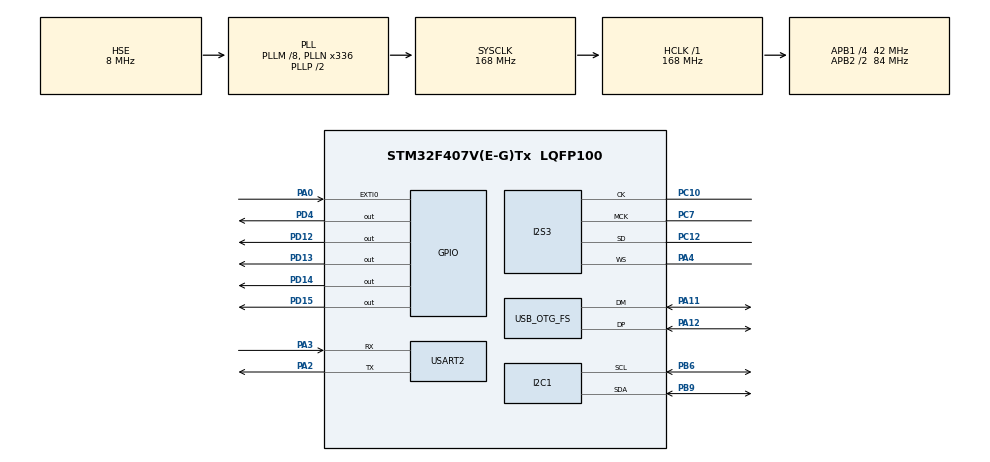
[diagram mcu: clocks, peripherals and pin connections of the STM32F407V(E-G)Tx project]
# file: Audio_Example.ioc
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Dma.Request0=SPI3_TX
Dma.Request1=USART2_RX
Dma.SPI3_TX.0.Direction=DMA_MEMORY_TO_PERIPH
Dma.SPI3_TX.0.FIFOMode=DMA_FIFOMODE_ENABLE
Dma.SPI3_TX.0.FIFOThreshold=DMA_FIFO_THRESHOLD_FULL
Dma.SPI3_TX.0.Instance=DMA1_Stream7
Dma.SPI3_TX.0.MemBurst=DMA_MBURST_SINGLE
Dma.SPI3_TX.0.MemDataAlignment=DMA_MDATAALIGN_HALFWORD
Dma.SPI3_TX.0.MemInc=DMA_MINC_ENABLE
Dma.SPI3_TX.0.Mode=DMA_CIRCULAR
Dma.SPI3_TX.0.PeriphBurst=DMA_PBURST_SINGLE
Dma.SPI3_TX.0.PeriphDataAlignment=DMA_PDATAALIGN_HALFWORD
Dma.SPI3_TX.0.PeriphInc=DMA_PINC_DISABLE
Dma.SPI3_TX.0.Priority=DMA_PRIORITY_LOW
Dma.USART2_RX.1.Direction=DMA_PERIPH_TO_MEMORY
Dma.USART2_RX.1.FIFOMode=DMA_FIFOMODE_DISABLE
Dma.USART2_RX.1.Instance=DMA1_Stream5
Dma.USART2_RX.1.MemDataAlignment=DMA_MDATAALIGN_BYTE
Dma.USART2_RX.1.MemInc=DMA_MINC_ENABLE
Dma.USART2_RX.1.Mode=DMA_NORMAL
Dma.USART2_RX.1.PeriphDataAlignment=DMA_PDATAALIGN_BYTE
Dma.USART2_RX.1.PeriphInc=DMA_PINC_DISABLE
Dma.USART2_RX.1.Priority=DMA_PRIORITY_LOW
I2S3.AudioFreq=I2S_AUDIOFREQ_48K
I2S3.ErrorAudioFreq=-2.34 %
I2S3.FullDuplexMode=I2S_FULLDUPLEXMODE_DISABLE
I2S3.Instance=SPI$Index
I2S3.RealAudioFreq=46.875 KHz
I2S3.VirtualMode=I2S_MODE_MASTER
Mcu.Family=STM32F4
Mcu.Name=STM32F407V(E-G)Tx
Mcu.Package=LQFP100
NVIC.DMA1_Stream5_IRQn=true\:0\:0\:false\:false\:true\:false\:true\:true
NVIC.DMA1_Stream7_IRQn=true\:0\:0\:false\:false\:true\:false\:true\:true
NVIC.EXTI0_IRQn=true\:0\:0\:false\:false\:true\:true\:true\:true
NVIC.OTG_FS_IRQn=true\:0\:0\:false\:false\:true\:false\:true\:true
NVIC.PriorityGroup=NVIC_PRIORITYGROUP_0
PA0-WKUP.Signal=GPXTI0
PA11.Mode=Device_Only
PA11.Signal=USB_OTG_FS_DM
PA12.Mode=Device_Only
PA12.Signal=USB_OTG_FS_DP
PA13.Mode=Serial_Wire
PA13.Signal=SYS_JTMS-SWDIO
PA14.Mode=Serial_Wire
PA14.Signal=SYS_JTCK-SWCLK
PA2.Mode=Asynchronous
PA2.Signal=USART2_TX
PA3.Mode=Asynchronous
PA3.Signal=USART2_RX
PA4.Mode=Half_Duplex_Master
PA4.Signal=I2S3_WS
PB6.Mode=I2C
PB6.Signal=I2C1_SCL
PB9.Mode=I2C
PB9.Signal=I2C1_SDA
PC10.Mode=Half_Duplex_Master
PC10.Signal=I2S3_CK
PC12.Mode=Half_Duplex_Master
PC12.Signal=I2S3_SD
PC7.Mode=Master_Clock_Activated
PC7.Signal=I2S3_MCK
PD12.Signal=GPIO_Output
PD13.Signal=GPIO_Output
PD14.Signal=GPIO_Output
PD15.Signal=GPIO_Output
PD4.Signal=GPIO_Output
PH0-OSC_IN.Mode=HSE-External-Oscillator
PH0-OSC_IN.Signal=RCC_OSC_IN
PH1-OSC_OUT.Mode=HSE-External-Oscillator
PH1-OSC_OUT.Signal=RCC_OSC_OUT
ProjectManager.HeapSize=0x200
ProjectManager.StackSize=0x400
ProjectManager.TargetToolchain=STM32CubeIDE
RCC.48MHZClocksFreq_Value=48000000
RCC.AHBFreq_Value=168000000
RCC.APB1CLKDivider=RCC_HCLK_DIV4
RCC.APB1Freq_Value=42000000
RCC.APB1TimFreq_Value=84000000
RCC.APB2CLKDivider=RCC_HCLK_DIV2
RCC.APB2Freq_Value=84000000
RCC.APB2TimFreq_Value=168000000
RCC.CortexFreq_Value=168000000
RCC.HCLKFreq_Value=168000000
RCC.HSE_VALUE=8000000
RCC.HSI_VALUE=16000000
RCC.LSE_VALUE=32768
RCC.PLLM=8
RCC.PLLN=336
RCC.PLLQ=7
RCC.SYSCLKFreq_VALUE=168000000
RCC.SYSCLKSource=RCC_SYSCLKSOURCE_PLLCLK
RCC.VCOOutputFreq_Value=336000000
USART2.VirtualMode=VM_ASYNC
USB_DEVICE.CLASS_NAME_FS=CDC
USB_DEVICE.VirtualMode-CDC_FS=Cdc
USB_DEVICE.VirtualModeFS=Cdc_FS
USB_OTG_FS.VirtualMode=Device_Only
VP_USB_DEVICE_VS_USB_DEVICE_CDC_FS.Mode=CDC_FS
board=STM32F407G-DISC1

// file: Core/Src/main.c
/* USER CODE BEGIN Header */
/**
  ******************************************************************************
  * @file           : main.c
  * @brief          : Main program body
  ******************************************************************************
  * @attention
  *
  * Copyright (c) 2024 STMicroelectronics.
  * All rights reserved.
  *
  * This software is licensed under terms that can be found in the LICENSE file
  * in the root directory of this software component.
  * If no LICENSE file comes with this software, it is provided AS-IS.
  *
  ******************************************************************************
  */
/* USER CODE END Header */
#include "main.h"
#include "usb_device.h"

/* USER CODE BEGIN Includes */
#include "interface.h"
/* USER CODE END Includes */

I2C_HandleTypeDef hi2c1;

I2S_HandleTypeDef hi2s3;
DMA_HandleTypeDef hdma_spi3_tx;

UART_HandleTypeDef huart2;
DMA_HandleTypeDef hdma_usart2_rx;

void SystemClock_Config(void);
static void MX_GPIO_Init(void);
static void MX_DMA_Init(void);
static void MX_I2C1_Init(void);
static void MX_I2S3_Init(void);
static void MX_USART2_UART_Init(void);

int main(void)
{

  /* MCU Configuration--------------------------------------------------------*/

  /* Reset of all peripherals, Initializes the Flash interface and the Systick. */
  HAL_Init();

  /* Configure the system clock */
  SystemClock_Config();

  /* Initialize all configured peripherals */
  MX_GPIO_Init();
  MX_DMA_Init();
  MX_I2C1_Init();
  MX_I2S3_Init();
  MX_USB_DEVICE_Init();
  MX_USART2_UART_Init();
  /* USER CODE BEGIN 2 */

  	InterfaceInit(&huart2, hi2s3, hi2c1);

  /* USER CODE END 2 */

  /* Infinite loop */
  while (1)
  {

    /* USER CODE BEGIN 3 */
	 PlayerInterface(&huart2, hi2s3);
  }
  /* USER CODE END 3 */
}

void SystemClock_Config(void)
{
  RCC_OscInitTypeDef RCC_OscInitStruct = {0};
  RCC_ClkInitTypeDef RCC_ClkInitStruct = {0};

  /** Configure the main internal regulator output voltage
  */
  __HAL_RCC_PWR_CLK_ENABLE();
  __HAL_PWR_VOLTAGESCALING_CONFIG(PWR_REGULATOR_VOLTAGE_SCALE1);

  /** Initializes the RCC Oscillators according to the specified parameters
  * in the RCC_OscInitTypeDef structure.
  */
  RCC_OscInitStruct.OscillatorType = RCC_OSCILLATORTYPE_HSE;
  RCC_OscInitStruct.HSEState = RCC_HSE_ON;
  RCC_OscInitStruct.PLL.PLLState = RCC_PLL_ON;
  RCC_OscInitStruct.PLL.PLLSource = RCC_PLLSOURCE_HSE;
  RCC_OscInitStruct.PLL.PLLM = 8;
  RCC_OscInitStruct.PLL.PLLN = 336;
  RCC_OscInitStruct.PLL.PLLP = RCC_PLLP_DIV2;
  RCC_OscInitStruct.PLL.PLLQ = 7;
  if (HAL_RCC_OscConfig(&RCC_OscInitStruct) != HAL_OK)
  {
    Error_Handler();
  }

  /** Initializes the CPU, AHB and APB buses clocks
  */
  RCC_ClkInitStruct.ClockType = RCC_CLOCKTYPE_HCLK|RCC_CLOCKTYPE_SYSCLK
                              |RCC_CLOCKTYPE_PCLK1|RCC_CLOCKTYPE_PCLK2;
  RCC_ClkInitStruct.SYSCLKSource = RCC_SYSCLKSOURCE_PLLCLK;
  RCC_ClkInitStruct.AHBCLKDivider = RCC_SYSCLK_DIV1;
  RCC_ClkInitStruct.APB1CLKDivider = RCC_HCLK_DIV4;
  RCC_ClkInitStruct.APB2CLKDivider = RCC_HCLK_DIV2;

  if (HAL_RCC_ClockConfig(&RCC_ClkInitStruct, FLASH_LATENCY_5) != HAL_OK)
  {
    Error_Handler();
  }
}

static void MX_I2C1_Init(void)
{

  hi2c1.Instance = I2C1;
  hi2c1.Init.ClockSpeed = 100000;
  hi2c1.Init.DutyCycle = I2C_DUTYCYCLE_2;
  hi2c1.Init.OwnAddress1 = 0;
  hi2c1.Init.AddressingMode = I2C_ADDRESSINGMODE_7BIT;
  hi2c1.Init.DualAddressMode = I2C_DUALADDRESS_DISABLE;
  hi2c1.Init.OwnAddress2 = 0;
  hi2c1.Init.GeneralCallMode = I2C_GENERALCALL_DISABLE;
  hi2c1.Init.NoStretchMode = I2C_NOSTRETCH_DISABLE;
  if (HAL_I2C_Init(&hi2c1) != HAL_OK)
  {
    Error_Handler();
  }

}

static void MX_I2S3_Init(void)
{

  hi2s3.Instance = SPI3;
  hi2s3.Init.Mode = I2S_MODE_MASTER_TX;
  hi2s3.Init.Standard = I2S_STANDARD_PHILIPS;
  hi2s3.Init.DataFormat = I2S_DATAFORMAT_16B;
  hi2s3.Init.MCLKOutput = I2S_MCLKOUTPUT_ENABLE;
  hi2s3.Init.AudioFreq = I2S_AUDIOFREQ_48K;
  hi2s3.Init.CPOL = I2S_CPOL_LOW;
  hi2s3.Init.ClockSource = I2S_CLOCK_PLL;
  hi2s3.Init.FullDuplexMode = I2S_FULLDUPLEXMODE_DISABLE;
  if (HAL_I2S_Init(&hi2s3) != HAL_OK)
  {
    Error_Handler();
  }

}

static void MX_USART2_UART_Init(void)
{

  huart2.Instance = USART2;
  huart2.Init.BaudRate = 115200;
  huart2.Init.WordLength = UART_WORDLENGTH_8B;
  huart2.Init.StopBits = UART_STOPBITS_1;
  huart2.Init.Parity = UART_PARITY_NONE;
  huart2.Init.Mode = UART_MODE_TX_RX;
  huart2.Init.HwFlowCtl = UART_HWCONTROL_NONE;
  huart2.Init.OverSampling = UART_OVERSAMPLING_16;
  if (HAL_UART_Init(&huart2) != HAL_OK)
  {
    Error_Handler();
  }

}

static void MX_DMA_Init(void)
{

  /* DMA controller clock enable */
  __HAL_RCC_DMA1_CLK_ENABLE();

  /* DMA interrupt init */
  /* DMA1_Stream5_IRQn interrupt configuration */
  HAL_NVIC_SetPriority(DMA1_Stream5_IRQn, 0, 0);
  HAL_NVIC_EnableIRQ(DMA1_Stream5_IRQn);
  /* DMA1_Stream7_IRQn interrupt configuration */
  HAL_NVIC_SetPriority(DMA1_Stream7_IRQn, 0, 0);
  HAL_NVIC_EnableIRQ(DMA1_Stream7_IRQn);

}

static void MX_GPIO_Init(void)
{
  GPIO_InitTypeDef GPIO_InitStruct = {0};

  /* GPIO Ports Clock Enable */
  __HAL_RCC_GPIOH_CLK_ENABLE();
  __HAL_RCC_GPIOA_CLK_ENABLE();
  __HAL_RCC_GPIOD_CLK_ENABLE();
  __HAL_RCC_GPIOC_CLK_ENABLE();
  __HAL_RCC_GPIOB_CLK_ENABLE();

  /*Configure GPIO pin Output Level */
  HAL_GPIO_WritePin(GPIOD, GPIO_PIN_12|GPIO_PIN_13|GPIO_PIN_14|GPIO_PIN_15
                          |GPIO_PIN_4, GPIO_PIN_RESET);

  /*Configure GPIO pin : PA0 */
  GPIO_InitStruct.Pin = GPIO_PIN_0;
  GPIO_InitStruct.Mode = GPIO_MODE_IT_RISING;
  GPIO_InitStruct.Pull = GPIO_NOPULL;
  HAL_GPIO_Init(GPIOA, &GPIO_InitStruct);

  /*Configure GPIO pins : PD12 PD13 PD14 PD15
                           PD4 */
  GPIO_InitStruct.Pin = GPIO_PIN_12|GPIO_PIN_13|GPIO_PIN_14|GPIO_PIN_15
                          |GPIO_PIN_4;
  GPIO_InitStruct.Mode = GPIO_MODE_OUTPUT_PP;
  GPIO_InitStruct.Pull = GPIO_NOPULL;
  GPIO_InitStruct.Speed = GPIO_SPEED_FREQ_LOW;
  HAL_GPIO_Init(GPIOD, &GPIO_InitStruct);

  /* EXTI interrupt init*/
  HAL_NVIC_SetPriority(EXTI0_IRQn, 0, 0);
  HAL_NVIC_EnableIRQ(EXTI0_IRQn);

}

void Error_Handler(void)
{
  __disable_irq();
  while (1)
  {
  }
}
